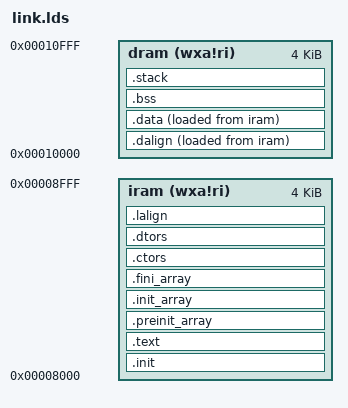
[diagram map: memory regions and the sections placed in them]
OUTPUT_ARCH( "riscv" )
ENTRY(_start)


_cpu_iram_base = 0x00008000; /*指令RAM基地址*/
_cpu_iram_size = 4K; /*指令RAM大小*/
_cpu_dram_base = 0x00010000; /*数据RAM基地址*/
_cpu_dram_size = 4K; /*数据RAM大小*/
_cpu_stack_size = 1K; /*栈区大小，必须小于数据RAM*/


/*定义存储器*/
MEMORY
{
  iram (wxa!ri) : ORIGIN = _cpu_iram_base, LENGTH = _cpu_iram_size 
  dram (wxa!ri) : ORIGIN = _cpu_dram_base, LENGTH = _cpu_dram_size 
}


SECTIONS
{
   __stack_size = DEFINED(__stack_size) ? __stack_size : _cpu_stack_size; 

  .init           :
  {
    KEEP (*(SORT_NONE(.init)))
  } >iram AT>iram 

  .text           :
  {
    *(.text.unlikely .text.unlikely.*)
    *(.text.startup .text.startup.*)
    *(.text .text.*)
    *(.gnu.linkonce.t.*)
  } >iram AT>iram 

  . = ALIGN(4);

  PROVIDE (__etext = .);
  PROVIDE (_etext = .);
  PROVIDE (etext = .);

  .preinit_array  :
  {
    PROVIDE_HIDDEN (__preinit_array_start = .);
    KEEP (*(.preinit_array))
    PROVIDE_HIDDEN (__preinit_array_end = .);
  } >iram AT>iram 

  .init_array     :
  {
    PROVIDE_HIDDEN (__init_array_start = .);
    KEEP (*(SORT_BY_INIT_PRIORITY(.init_array.*) SORT_BY_INIT_PRIORITY(.ctors.*)))
    KEEP (*(.init_array EXCLUDE_FILE (*crtbegin.o *crtbegin?.o *crtend.o *crtend?.o ) .ctors))
    PROVIDE_HIDDEN (__init_array_end = .);
  } >iram AT>iram 

  .fini_array     :
  {
    PROVIDE_HIDDEN (__fini_array_start = .);
    KEEP (*(SORT_BY_INIT_PRIORITY(.fini_array.*) SORT_BY_INIT_PRIORITY(.dtors.*)))
    KEEP (*(.fini_array EXCLUDE_FILE (*crtbegin.o *crtbegin?.o *crtend.o *crtend?.o ) .dtors))
    PROVIDE_HIDDEN (__fini_array_end = .);
  } >iram AT>iram 

  .ctors          :
  {
    /* gcc uses crtbegin.o to find the start of
       the constructors, so we make sure it is
       first.  Because this is a wildcard, it
       doesn't matter if the user does not
       actually link against crtbegin.o; the
       linker won't look for a file to match a
       wildcard.  The wildcard also means that it
       doesn't matter which directory crtbegin.o
       is in.  */
    KEEP (*crtbegin.o(.ctors))
    KEEP (*crtbegin?.o(.ctors))
    /* We don't want to include the .ctor section from
       the crtend.o file until after the sorted ctors.
       The .ctor section from the crtend file contains the
       end of ctors marker and it must be last */
    KEEP (*(EXCLUDE_FILE (*crtend.o *crtend?.o ) .ctors))
    KEEP (*(SORT(.ctors.*)))
    KEEP (*(.ctors))
  } >iram AT>iram 

  .dtors          :
  {
    KEEP (*crtbegin.o(.dtors))
    KEEP (*crtbegin?.o(.dtors))
    KEEP (*(EXCLUDE_FILE (*crtend.o *crtend?.o ) .dtors))
    KEEP (*(SORT(.dtors.*)))
    KEEP (*(.dtors))
  } >iram AT>iram 

  .lalign         :
  {
    . = ALIGN(4);
    PROVIDE( _data_lma = . );
  } >iram AT>iram 

  .dalign         :
  {
    . = ALIGN(4);
    PROVIDE( _data = . );
  } >dram AT>iram 

  .data          :
  {
    *(.rdata)
    *(.rodata .rodata.*)
    *(.gnu.linkonce.r.*)
    *(.data .data.*)
    *(.gnu.linkonce.d.*)
    . = ALIGN(8);
    PROVIDE( __global_pointer$ = . + 0x800 );
    *(.sdata .sdata.*)
    *(.gnu.linkonce.s.*)
    . = ALIGN(8);
    *(.srodata.cst16)
    *(.srodata.cst8)
    *(.srodata.cst4)
    *(.srodata.cst2)
    *(.srodata .srodata.*)
  } >dram AT>iram 

  . = ALIGN(4);
  PROVIDE( _edata = . );
  PROVIDE( edata = . );

  PROVIDE( _fbss = . );
  PROVIDE( __bss_start = . );
  .bss            :
  {
    *(.sbss*)
    *(.gnu.linkonce.sb.*)
    *(.bss .bss.*)
    *(.gnu.linkonce.b.*)
    *(COMMON)
    . = ALIGN(4);
  } >dram AT>dram 

  . = ALIGN(8);
  PROVIDE( _end = . );
  PROVIDE( end = . );

  .stack ORIGIN(dram) + LENGTH(dram) - __stack_size :
  {
    PROVIDE( _heap_end = . );
    . = __stack_size;
    PROVIDE( _sp = . );
  } >dram AT>dram

}
